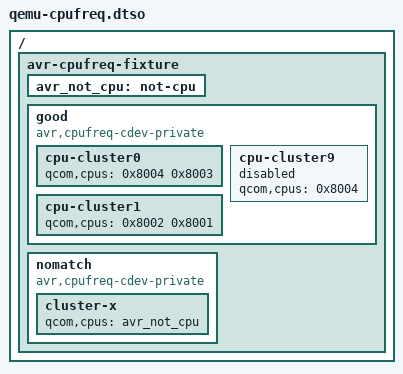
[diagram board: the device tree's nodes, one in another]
/dts-v1/;
/plugin/;
/* Cluster layout mirrors saved AVR qcom,cpufreq-cdev; 0x8004..0x8001 are QEMU
 * virt -smp 4 cpu@0..3 phandles (checked by the test, never an AVR DT). */
/ { fragment@0 { target-path="/"; __overlay__ {
 avr-cpufreq-fixture {
  avr_not_cpu: not-cpu { };
  good {
   compatible="avr,cpufreq-cdev-private";
   cpu-cluster0 { qcom,cpus=<0x8004 0x8003>; };
   cpu-cluster1 { qcom,cpus=<0x8002 0x8001>; };
   cpu-cluster9 { status="disabled"; qcom,cpus=<0x8004>; };
  };
  nomatch {
   compatible="avr,cpufreq-cdev-private";
   cluster-x { qcom,cpus=<&avr_not_cpu>; };
  };
 };
}; }; };
